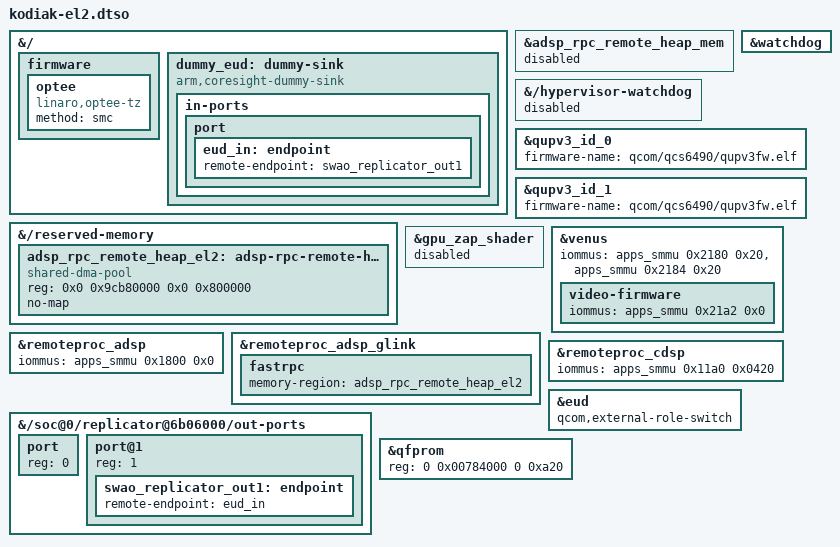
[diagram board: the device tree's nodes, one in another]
// SPDX-License-Identifier: BSD-3-Clause
/*
 * Kodiak (SC7280 / QCS6490) modifications required to boot Linux in EL2
 * under TF-A + OP-TEE (no Gunyah/QHEE hypervisor).
 */

/dts-v1/;
/plugin/;

&{/} {
	firmware {
		optee {
			compatible = "linaro,optee-tz";
			method = "smc";
		};
	};

	dummy_eud: dummy-sink {
		compatible = "arm,coresight-dummy-sink";

		in-ports {
			port {
				eud_in: endpoint {
					remote-endpoint = <&swao_replicator_out1>;
				};
			};
		};
	};
};

&{/reserved-memory} {
	#address-cells = <2>;
	#size-cells = <2>;

	/*
	 * Pin ADSP FastRPC remote heap to the fixed 8 MiB address (0x9cb80000)
	 * shared with U-Boot and OP-TEE PAS lpass_mem_res[] so SID 0x1800 maps
	 * the exact physical range under EL2 SMMU without dynamic CMA drift.
	 */
	adsp_rpc_remote_heap_el2: adsp-rpc-remote-heap@9cb80000 {
		compatible = "shared-dma-pool";
		reg = <0x0 0x9cb80000 0x0 0x800000>;
		no-map;
	};
};

&adsp_rpc_remote_heap_mem {
	status = "disabled";
};

&{/hypervisor-watchdog} {
	status = "disabled";
};

&watchdog {
	status = "okay";
};

&qupv3_id_0 {
	firmware-name = "qcom/qcs6490/qupv3fw.elf";
};

&qupv3_id_1 {
	firmware-name = "qcom/qcs6490/qupv3fw.elf";
};

&gpu_zap_shader {
	status = "disabled";
};

&venus {
	iommus = <&apps_smmu 0x2180 0x20>,
		 <&apps_smmu 0x2184 0x20>;

	video-firmware {
		iommus = <&apps_smmu 0x21a2 0x0>;
	};
};

&remoteproc_adsp {
	iommus = <&apps_smmu 0x1800 0x0>;
};

&remoteproc_adsp_glink {
	fastrpc {
		memory-region = <&adsp_rpc_remote_heap_el2>;
	};
};

&remoteproc_cdsp {
	iommus = <&apps_smmu 0x11a0 0x0420>;
};

&{/soc@0/replicator@6b06000/out-ports} {
	#address-cells = <1>;
	#size-cells = <0>;

	port {
		reg = <0>;
	};

	port@1 {
		reg = <1>;

		swao_replicator_out1: endpoint {
			remote-endpoint = <&eud_in>;
		};
	};
};

&eud {
	qcom,external-role-switch;
	status = "okay";
};

/*
 * Under TF-A + OP-TEE (EL2), Qualcomm TZ ICE SCM is not present and QFPROM is
 * read-only (no TZ GCC_SEC_CTRL_CLK_SRC / fuse-blow rail).
 */
&qfprom {
	reg = <0 0x00784000 0 0xa20>;
	/delete-property/ clocks;
	/delete-property/ clock-names;
};
